# nrf9120_mlm1 register map
Vendor: Nordic Semiconductor; Series: nrf91; File version: 1
CPU: CM4 r0p1, little endian, MPU, FPU, 3 interrupt priority bits
Registers are 32-bit, read-write, reset 0x0 unless marked. A register's access mark holds for its fields unless they carry their own. Offsets are from the block's base; [hi:lo] are bit positions; lines under a group give offsets from that group; {n}, {i} and the like mark numbered series; 'fields as' and 'values as' point back to an identical list.

## USBD — Universal Serial Bus device
Base 0x4001F000
0x00 TASKS_USBDREINIT wo — Resets the whole USBD peripheral. This includes disabling the pull-up on D+.
  [0] TASKS_USBDREINIT
    1=Trigger task
{0x4+4i} TASKS_STARTEPIN[{i}] (i=0..7) wo — Description collection: Captures the EPIN[n].PTR, EPIN[n].MAXCNT and EPIN[n].CONFIG registers values, and enables endpoint IN n to respond to traffic from host
  [0] TASKS_STARTEPIN — Captures the EPIN[n].PTR, EPIN[n].MAXCNT and EPIN[n].CONFIG registers values, and enables endpoint IN n to respond to traffic from host
    1=Trigger task
{0x24+4i} TASKS_STARTISOIN[{i}] (i=0..0) wo — Description collection: Captures the ISOIN[n].PTR, ISOIN[n].MAXCNT and ISOIN[n].CONFIG registers values, and enables sending data on iso endpoint
  [0] TASKS_STARTISOIN — Captures the ISOIN[n].PTR, ISOIN[n].MAXCNT and ISOIN[n].CONFIG registers values, and enables sending data on iso endpoint
    1=Trigger task
{0x28+4i} TASKS_STARTEPOUT[{i}] (i=0..7) wo — Description collection: Captures the EPOUT[n].PTR, EPOUT[n].MAXCNT and EPOUT[n].CONFIG registers values, and enables endpoint n to respond to traffic from host
  [0] TASKS_STARTEPOUT — Captures the EPOUT[n].PTR, EPOUT[n].MAXCNT and EPOUT[n].CONFIG registers values, and enables endpoint n to respond to traffic from host
    1=Trigger task
{0x48+4i} TASKS_STARTISOOUT[{i}] (i=0..0) wo — Description collection: Captures the ISOOUT[n].PTR, ISOOUT[n].MAXCNT and ISOOUT[n].CONFIG registers values, and enables receiving of data on iso endpoint
  [0] TASKS_STARTISOOUT — Captures the ISOOUT[n].PTR, ISOOUT[n].MAXCNT and ISOOUT[n].CONFIG registers values, and enables receiving of data on iso endpoint
    1=Trigger task
0x4C TASKS_EP0RCVOUT wo — Allows OUT data stage on control endpoint 0
  [0] TASKS_EP0RCVOUT
    1=Trigger task
0x50 TASKS_EP0STATUS wo — Allows status stage on control endpoint 0
  [0] TASKS_EP0STATUS
    1=Trigger task
0x54 TASKS_EP0STALL wo — STALLs data and status stage on control endpoint 0
  [0] TASKS_EP0STALL
    1=Trigger task
0x58 TASKS_DPDMDRIVE wo — Forces D+ and D-lines to the state defined in the DPDMVALUE register
  [0] TASKS_DPDMDRIVE
    1=Trigger task
0x5C TASKS_DPDMNODRIVE wo — Stops forcing D+ and D- lines to any state (USB engine takes control)
  [0] TASKS_DPDMNODRIVE
    1=Trigger task
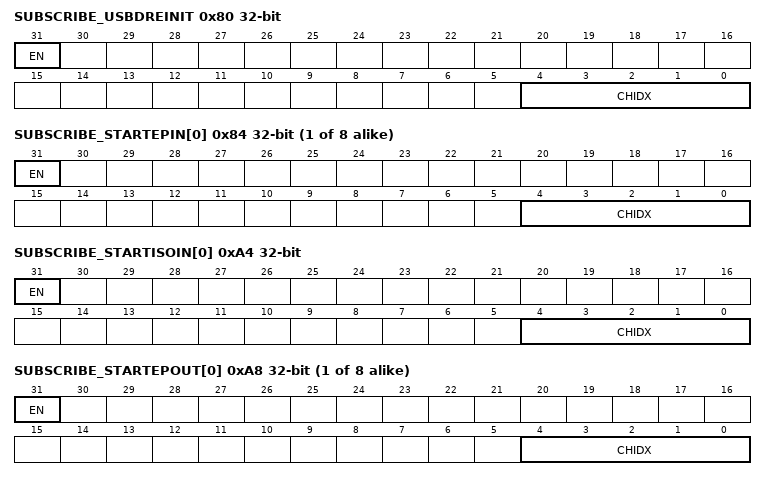
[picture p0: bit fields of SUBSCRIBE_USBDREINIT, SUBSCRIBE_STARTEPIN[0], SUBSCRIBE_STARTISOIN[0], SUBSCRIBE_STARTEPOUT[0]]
0x80 SUBSCRIBE_USBDREINIT — Subscribe configuration for task USBDREINIT
  [31] EN
    0=Disabled (Disable subscription); 1=Enabled (Enable subscription)
  [4:0] CHIDX — Channel that task USBDREINIT will subscribe to
{0x84+4i} SUBSCRIBE_STARTEPIN[{i}] (i=0..7) — Description collection: Subscribe configuration for task STARTEPIN[n]
  [31] EN
    values as SUBSCRIBE_USBDREINIT.EN
  [4:0] CHIDX — Channel that task STARTEPIN[n] will subscribe to
{0xA4+4i} SUBSCRIBE_STARTISOIN[{i}] (i=0..0) — Description collection: Subscribe configuration for task STARTISOIN[n]
  [31] EN
    values as SUBSCRIBE_USBDREINIT.EN
  [4:0] CHIDX — Channel that task STARTISOIN[n] will subscribe to
{0xA8+4i} SUBSCRIBE_STARTEPOUT[{i}] (i=0..7) — Description collection: Subscribe configuration for task STARTEPOUT[n]
  [31] EN
    values as SUBSCRIBE_USBDREINIT.EN
  [4:0] CHIDX — Channel that task STARTEPOUT[n] will subscribe to
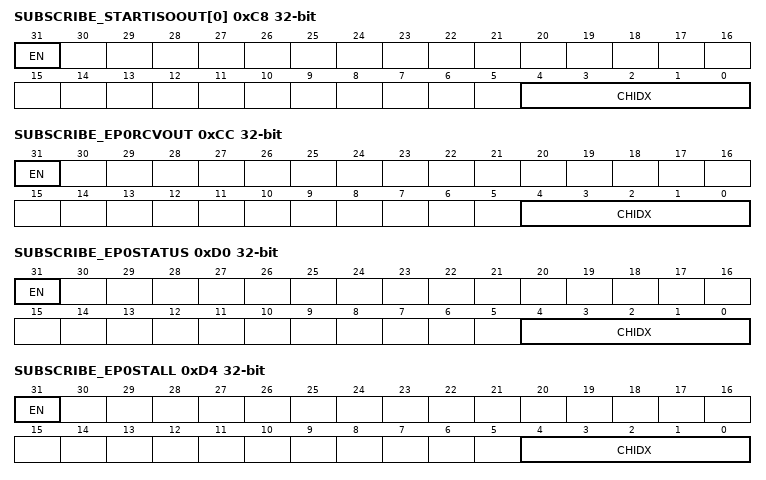
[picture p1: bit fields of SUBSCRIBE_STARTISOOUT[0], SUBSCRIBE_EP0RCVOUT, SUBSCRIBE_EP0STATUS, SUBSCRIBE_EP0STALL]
{0xC8+4i} SUBSCRIBE_STARTISOOUT[{i}] (i=0..0) — Description collection: Subscribe configuration for task STARTISOOUT[n]
  [31] EN
    values as SUBSCRIBE_USBDREINIT.EN
  [4:0] CHIDX — Channel that task STARTISOOUT[n] will subscribe to
0xCC SUBSCRIBE_EP0RCVOUT — Subscribe configuration for task EP0RCVOUT
  [31] EN
    values as SUBSCRIBE_USBDREINIT.EN
  [4:0] CHIDX — Channel that task EP0RCVOUT will subscribe to
0xD0 SUBSCRIBE_EP0STATUS — Subscribe configuration for task EP0STATUS
  [31] EN
    values as SUBSCRIBE_USBDREINIT.EN
  [4:0] CHIDX — Channel that task EP0STATUS will subscribe to
0xD4 SUBSCRIBE_EP0STALL — Subscribe configuration for task EP0STALL
  [31] EN
    values as SUBSCRIBE_USBDREINIT.EN
  [4:0] CHIDX — Channel that task EP0STALL will subscribe to
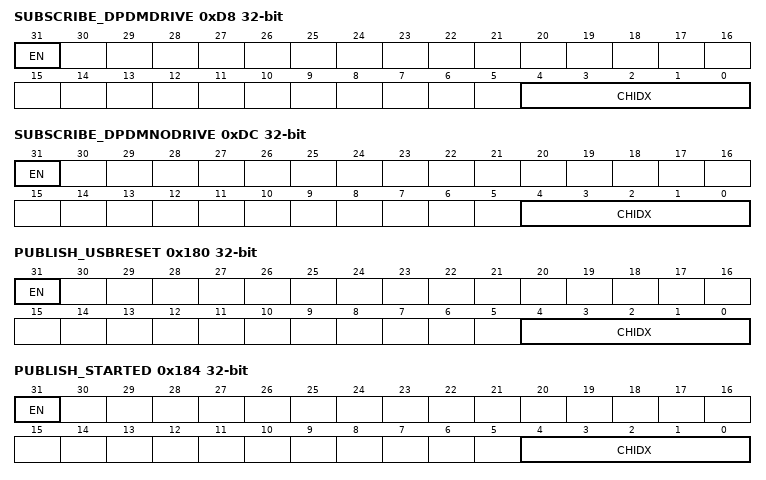
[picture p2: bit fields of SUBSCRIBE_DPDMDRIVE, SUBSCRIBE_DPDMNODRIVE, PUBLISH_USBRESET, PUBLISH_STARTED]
0xD8 SUBSCRIBE_DPDMDRIVE — Subscribe configuration for task DPDMDRIVE
  [31] EN
    values as SUBSCRIBE_USBDREINIT.EN
  [4:0] CHIDX — Channel that task DPDMDRIVE will subscribe to
0xDC SUBSCRIBE_DPDMNODRIVE — Subscribe configuration for task DPDMNODRIVE
  [31] EN
    values as SUBSCRIBE_USBDREINIT.EN
  [4:0] CHIDX — Channel that task DPDMNODRIVE will subscribe to
0x100 EVENTS_USBRESET — Signals that a USB reset condition has been detected on the USB lines
  [0] EVENTS_USBRESET
    0=NotGenerated (Event not generated); 1=Generated (Event generated)
0x104 EVENTS_STARTED — Confirms that the EPIN[n].PTR, EPIN[n].MAXCNT, EPIN[n].CONFIG, or EPOUT[n].PTR, EPOUT[n].MAXCNT and EPOUT[n].CONFIG registers have been captured on all endpoints reported in the EPSTATUS register
  [0] EVENTS_STARTED
    values as EVENTS_USBRESET.EVENTS_USBRESET
{0x108+4i} EVENTS_ENDEPIN[{i}] (i=0..7) — Description collection: The whole EPIN[n] buffer has been consumed. The RAM buffer can be accessed safely by software.
  [0] EVENTS_ENDEPIN — The whole EPIN[n] buffer has been consumed. The RAM buffer can be accessed safely by software.
    values as EVENTS_USBRESET.EVENTS_USBRESET
0x128 EVENTS_EP0DATADONE — An acknowledged data transfer has taken place on the control endpoint
  [0] EVENTS_EP0DATADONE
    values as EVENTS_USBRESET.EVENTS_USBRESET
{0x12C+4i} EVENTS_ENDISOIN[{i}] (i=0..0) — Description collection: The whole ISOIN[n] buffer has been consumed. The RAM buffer can be accessed safely by software.
  [0] EVENTS_ENDISOIN — The whole ISOIN[n] buffer has been consumed. The RAM buffer can be accessed safely by software.
    values as EVENTS_USBRESET.EVENTS_USBRESET
{0x130+4i} EVENTS_ENDEPOUT[{i}] (i=0..7) — Description collection: The whole EPOUT[n] buffer has been consumed. The RAM buffer can be accessed safely by software.
  [0] EVENTS_ENDEPOUT — The whole EPOUT[n] buffer has been consumed. The RAM buffer can be accessed safely by software.
    values as EVENTS_USBRESET.EVENTS_USBRESET
{0x150+4i} EVENTS_ENDISOOUT[{i}] (i=0..0) — Description collection: The whole ISOOUT[n] buffer has been consumed. The RAM buffer can be accessed safely by software.
  [0] EVENTS_ENDISOOUT — The whole ISOOUT[n] buffer has been consumed. The RAM buffer can be accessed safely by software.
    values as EVENTS_USBRESET.EVENTS_USBRESET
0x154 EVENTS_SOF — Signals that a SOF (start of frame) condition has been detected on the USB lines
  [0] EVENTS_SOF
    values as EVENTS_USBRESET.EVENTS_USBRESET
0x158 EVENTS_USBEVENT — An event or an error not covered by specific events has occurred, check EVENTCAUSE register to find the cause
  [0] EVENTS_USBEVENT
    values as EVENTS_USBRESET.EVENTS_USBRESET
0x15C EVENTS_EP0SETUP — A valid SETUP token has been received (and acknowledged) on the control endpoint
  [0] EVENTS_EP0SETUP
    values as EVENTS_USBRESET.EVENTS_USBRESET
0x160 EVENTS_EPDATA — A data transfer has occurred on a data endpoint, indicated by the EPDATASTATUS register
  [0] EVENTS_EPDATA
    values as EVENTS_USBRESET.EVENTS_USBRESET
0x164 EVENTS_ACCESSFAULT — Access to an unavailable USB register has been attempted (software or EasyDMA). This event can get fired even when USBD is not ENABLEd.
  [0] EVENTS_ACCESSFAULT
    values as EVENTS_USBRESET.EVENTS_USBRESET
0x180 PUBLISH_USBRESET — Publish configuration for event USBRESET
  [31] EN
    0=Disabled (Disable publishing); 1=Enabled (Enable publishing)
  [4:0] CHIDX — Channel that event USBRESET will publish to.
0x184 PUBLISH_STARTED — Publish configuration for event STARTED
  [31] EN
    values as PUBLISH_USBRESET.EN
  [4:0] CHIDX — Channel that event STARTED will publish to.
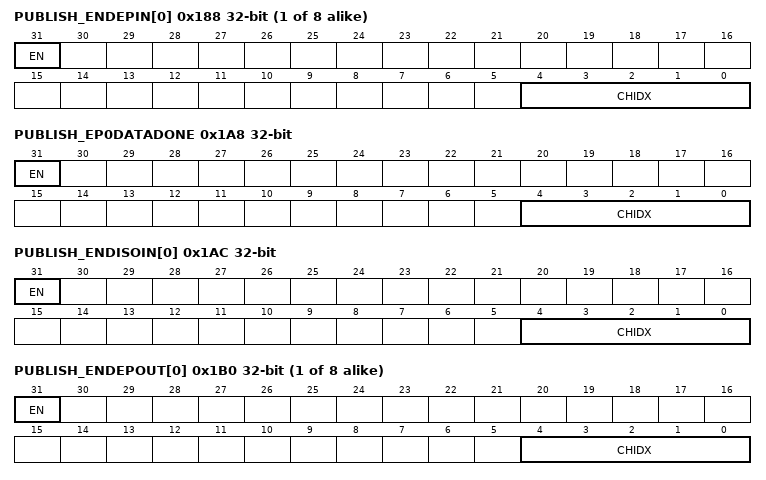
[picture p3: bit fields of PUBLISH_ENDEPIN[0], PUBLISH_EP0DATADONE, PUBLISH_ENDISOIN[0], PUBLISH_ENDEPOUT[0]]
{0x188+4i} PUBLISH_ENDEPIN[{i}] (i=0..7) — Description collection: Publish configuration for event ENDEPIN[n]
  [31] EN
    values as PUBLISH_USBRESET.EN
  [4:0] CHIDX — Channel that event ENDEPIN[n] will publish to.
0x1A8 PUBLISH_EP0DATADONE — Publish configuration for event EP0DATADONE
  [31] EN
    values as PUBLISH_USBRESET.EN
  [4:0] CHIDX — Channel that event EP0DATADONE will publish to.
{0x1AC+4i} PUBLISH_ENDISOIN[{i}] (i=0..0) — Description collection: Publish configuration for event ENDISOIN[n]
  [31] EN
    values as PUBLISH_USBRESET.EN
  [4:0] CHIDX — Channel that event ENDISOIN[n] will publish to.
{0x1B0+4i} PUBLISH_ENDEPOUT[{i}] (i=0..7) — Description collection: Publish configuration for event ENDEPOUT[n]
  [31] EN
    values as PUBLISH_USBRESET.EN
  [4:0] CHIDX — Channel that event ENDEPOUT[n] will publish to.
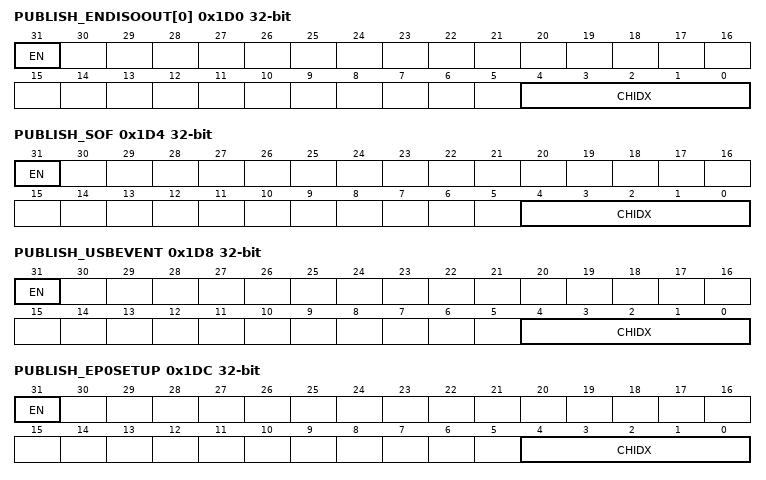
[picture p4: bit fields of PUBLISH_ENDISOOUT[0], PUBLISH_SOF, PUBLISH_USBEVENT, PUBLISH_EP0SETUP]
{0x1D0+4i} PUBLISH_ENDISOOUT[{i}] (i=0..0) — Description collection: Publish configuration for event ENDISOOUT[n]
  [31] EN
    values as PUBLISH_USBRESET.EN
  [4:0] CHIDX — Channel that event ENDISOOUT[n] will publish to.
0x1D4 PUBLISH_SOF — Publish configuration for event SOF
  [31] EN
    values as PUBLISH_USBRESET.EN
  [4:0] CHIDX — Channel that event SOF will publish to.
0x1D8 PUBLISH_USBEVENT — Publish configuration for event USBEVENT
  [31] EN
    values as PUBLISH_USBRESET.EN
  [4:0] CHIDX — Channel that event USBEVENT will publish to.
0x1DC PUBLISH_EP0SETUP — Publish configuration for event EP0SETUP
  [31] EN
    values as PUBLISH_USBRESET.EN
  [4:0] CHIDX — Channel that event EP0SETUP will publish to.
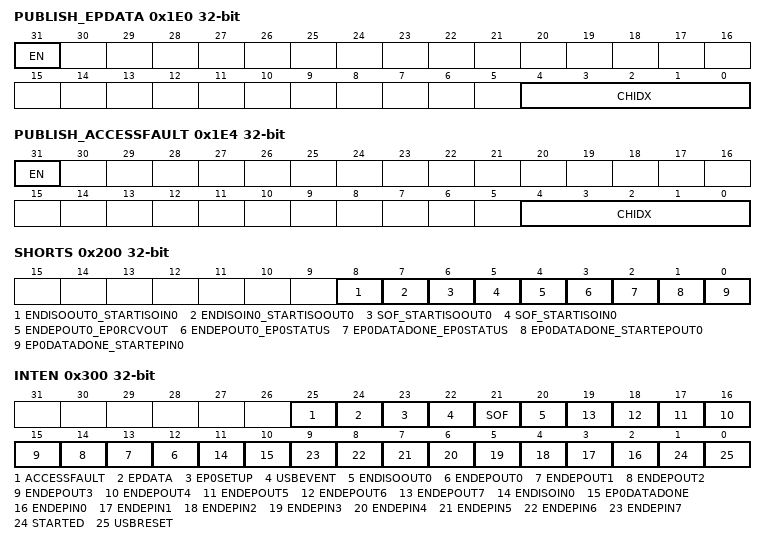
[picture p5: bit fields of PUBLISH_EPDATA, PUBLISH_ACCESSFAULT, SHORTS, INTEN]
0x1E0 PUBLISH_EPDATA — Publish configuration for event EPDATA
  [31] EN
    values as PUBLISH_USBRESET.EN
  [4:0] CHIDX — Channel that event EPDATA will publish to.
0x1E4 PUBLISH_ACCESSFAULT — Publish configuration for event ACCESSFAULT
  [31] EN
    values as PUBLISH_USBRESET.EN
  [4:0] CHIDX — Channel that event ACCESSFAULT will publish to.
0x200 SHORTS — Shortcuts between local events and tasks
  [all] fields
    0=Disabled (Disable shortcut); 1=Enabled (Enable shortcut)
  [8] ENDISOOUT0_STARTISOIN0 — Shortcut between event ENDISOOUT[0] and task STARTISOIN[0]
  [7] ENDISOIN0_STARTISOOUT0 — Shortcut between event ENDISOIN[0] and task STARTISOOUT[0]
  [6] SOF_STARTISOOUT0 — Shortcut between event SOF and task STARTISOOUT[0]
  [5] SOF_STARTISOIN0 — Shortcut between event SOF and task STARTISOIN[0]
  [4] ENDEPOUT0_EP0RCVOUT — Shortcut between event ENDEPOUT[0] and task EP0RCVOUT
  [3] ENDEPOUT0_EP0STATUS — Shortcut between event ENDEPOUT[0] and task EP0STATUS
  [2] EP0DATADONE_EP0STATUS — Shortcut between event EP0DATADONE and task EP0STATUS
  [1] EP0DATADONE_STARTEPOUT0 — Shortcut between event EP0DATADONE and task STARTEPOUT[0]
  [0] EP0DATADONE_STARTEPIN0 — Shortcut between event EP0DATADONE and task STARTEPIN[0]
0x300 INTEN — Enable or disable interrupt
  [all] fields
    0=Disabled; 1=Enabled
  [25] ACCESSFAULT — Enable or disable interrupt for event ACCESSFAULT
  [24] EPDATA — Enable or disable interrupt for event EPDATA
  [23] EP0SETUP — Enable or disable interrupt for event EP0SETUP
  [22] USBEVENT — Enable or disable interrupt for event USBEVENT
  [21] SOF — Enable or disable interrupt for event SOF
  [20] ENDISOOUT0 — Enable or disable interrupt for event ENDISOOUT[0]
  [n+12] ENDEPOUT{n} (n=0..7) — Enable or disable interrupt for event ENDEPOUT[{n}]
  [11] ENDISOIN0 — Enable or disable interrupt for event ENDISOIN[0]
  [10] EP0DATADONE — Enable or disable interrupt for event EP0DATADONE
  [n+2] ENDEPIN{n} (n=0..7) — Enable or disable interrupt for event ENDEPIN[{n}]
  [1] STARTED — Enable or disable interrupt for event STARTED
  [0] USBRESET — Enable or disable interrupt for event USBRESET
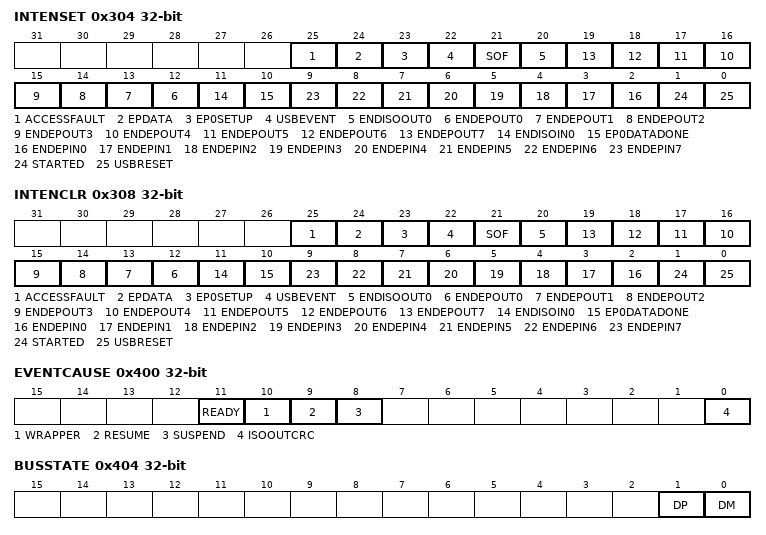
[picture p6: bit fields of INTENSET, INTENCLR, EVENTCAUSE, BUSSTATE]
0x304 INTENSET — Enable interrupt
  [all] fields
    on read: 0=Disabled (Read: Disabled); 1=Enabled (Read: Enabled) | on write: 1=Set (Enable)
  [25] ACCESSFAULT — Write '1' to enable interrupt for event ACCESSFAULT
  [24] EPDATA — Write '1' to enable interrupt for event EPDATA
  [23] EP0SETUP — Write '1' to enable interrupt for event EP0SETUP
  [22] USBEVENT — Write '1' to enable interrupt for event USBEVENT
  [21] SOF — Write '1' to enable interrupt for event SOF
  [20] ENDISOOUT0 — Write '1' to enable interrupt for event ENDISOOUT[0]
  [n+12] ENDEPOUT{n} (n=0..7) — Write '1' to enable interrupt for event ENDEPOUT[{n}]
  [11] ENDISOIN0 — Write '1' to enable interrupt for event ENDISOIN[0]
  [10] EP0DATADONE — Write '1' to enable interrupt for event EP0DATADONE
  [n+2] ENDEPIN{n} (n=0..7) — Write '1' to enable interrupt for event ENDEPIN[{n}]
  [1] STARTED — Write '1' to enable interrupt for event STARTED
  [0] USBRESET — Write '1' to enable interrupt for event USBRESET
0x308 INTENCLR — Disable interrupt
  [all] fields
    on read: 0=Disabled (Read: Disabled); 1=Enabled (Read: Enabled) | on write: 1=Clear (Disable)
  [25] ACCESSFAULT — Write '1' to disable interrupt for event ACCESSFAULT
  [24] EPDATA — Write '1' to disable interrupt for event EPDATA
  [23] EP0SETUP — Write '1' to disable interrupt for event EP0SETUP
  [22] USBEVENT — Write '1' to disable interrupt for event USBEVENT
  [21] SOF — Write '1' to disable interrupt for event SOF
  [20] ENDISOOUT0 — Write '1' to disable interrupt for event ENDISOOUT[0]
  [n+12] ENDEPOUT{n} (n=0..7) — Write '1' to disable interrupt for event ENDEPOUT[{n}]
  [11] ENDISOIN0 — Write '1' to disable interrupt for event ENDISOIN[0]
  [10] EP0DATADONE — Write '1' to disable interrupt for event EP0DATADONE
  [n+2] ENDEPIN{n} (n=0..7) — Write '1' to disable interrupt for event ENDEPIN[{n}]
  [1] STARTED — Write '1' to disable interrupt for event STARTED
  [0] USBRESET — Write '1' to disable interrupt for event USBRESET
0x400 EVENTCAUSE write-1-clears — Details on event that caused the USBEVENT event
  [11] READY — Wrapper has re-initialized SFRs to the proper values. MAC is ready for normal operation. Write '1' to clear.
    0=NotDetected (USBEVENT was not issued due to USBD peripheral ready); 1=Ready (USBD peripheral is ready)
  [10] WRAPPER — USB MAC has been woken up by the wrapper. Reflects the wakesrc bit in usbcs SFR. Write '1' to clear.
    0=NotDetected (Condition not detected); 1=Detected (Condition detected)
  [9] RESUME — Signals that a RESUME condition (K state or activity restart) has been detected on the USB lines. Write '1' to clear.
    0=NotDetected (Resume not detected); 1=Detected (Resume detected)
  [8] SUSPEND — Signals that the USB lines have been seen idle long enough for the device to enter suspend. Write '1' to clear.
    0=NotDetected (Suspend not detected); 1=Detected (Suspend detected)
  [0] ISOOUTCRC — CRC error was detected on isochronous OUT endpoint 8. Write '1' to clear.
    0=NotDetected (No error detected); 1=Detected (Error detected)
0x404 BUSSTATE ro — Provides the logic state of the D+ and D- lines
  [1] DP — State of the D+ line
    0=Low; 1=High
  [0] DM — State of the D- line
    0=Low; 1=High
0x420 HALTED group — Unspecified
  {0x0+4j} EPIN[{j}] (j=0..7) ro — Description collection: IN endpoint halted status. Can be used as is as response to a GetStatus() request to endpoint.
    [15:0] GETSTATUS — IN endpoint halted status. Can be used as is as response to a GetStatus() request to endpoint.
      0=NotHalted (Endpoint is not halted); 1=Halted (Endpoint is halted)
  {0x24+4j} EPOUT[{j}] (j=0..7) ro — Description collection: OUT endpoint halted status. Can be used as is as response to a GetStatus() request to endpoint.
    [15:0] GETSTATUS — OUT endpoint halted status. Can be used as is as response to a GetStatus() request to endpoint.
      values as HALTED.EPIN[0].GETSTATUS
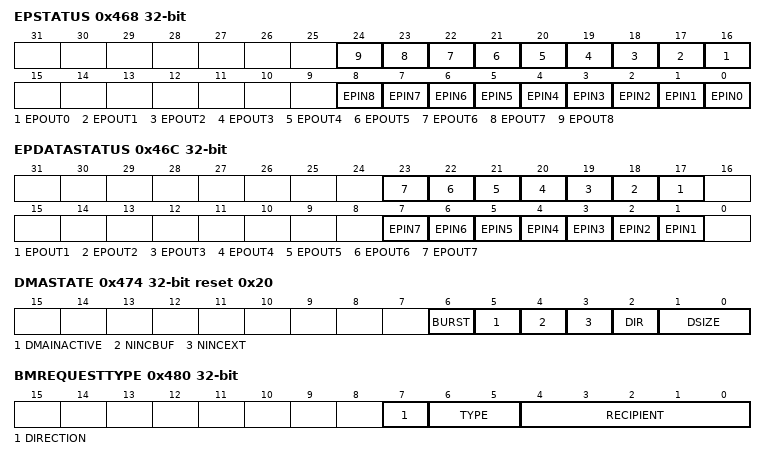
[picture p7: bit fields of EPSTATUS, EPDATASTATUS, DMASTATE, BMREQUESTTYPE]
0x468 EPSTATUS write-1-clears — Provides information on which endpoint's EasyDMA registers have been captured
  [all] fields
    0=NoData (EasyDMA registers have not been captured for this endpoint); 1=DataDone (EasyDMA registers have been captured for this endpoint)
  [n+16] EPOUT{n} (n=0..8) — Endpoint's EasyDMA registers captured state. Write '1' to clear.
  [n] EPIN{n} (n=0..8) — Endpoint's EasyDMA registers captured state. Write '1' to clear.
0x46C EPDATASTATUS write-1-clears — Provides information on which endpoint(s) an acknowledged data transfer has occurred (EPDATA event)
  [n+16] EPOUT{n} (n=1..7) — Acknowledged data transfer on this OUT endpoint. Write '1' to clear.
    0=NotStarted (No acknowledged data transfer on this endpoint); 1=Started (Acknowledged data transfer on this endpoint has occurred)
  [n] EPIN{n} (n=1..7) — Acknowledged data transfer on this IN endpoint. Write '1' to clear.
    0=NotDone (No acknowledged data transfer on this endpoint); 1=DataDone (Acknowledged data transfer on this endpoint has occurred)
0x470 USBADDR ro — Device USB address
  [6:0] ADDR
0x474 DMASTATE ro reset 0x20 — Indicates activity state of the DMA
  [6] BURST — DMA burst
    0=Single transfer; 1=Burst transfer
  [5] DMAINACTIVE — DMA active or not
    0=Active (DMA transfer on-going); 1=Inactive (No DMA transfer on-going)
  [4] NINCBUF — DMA no increment buffer address
    0=NoIncrement (Buffer address is not incremented after every access); 1=Increment (Buffer address is incremented after every access)
  [3] NINCEXT — DMA no increment external memory address
    0=NoIncrement (Data RAM address is not incremented after every access); 1=Increment (Data RAM address is incremented after every access)
  [2] DIR — DMA no increment external memory address
    0=ToRAM (DMA transfers from USB buffer to Data RAM); 1=ToUSB (DMA transfers from Data RAM to USB buffer)
  [1:0] DSIZE — DMA transfer size
    0=8 Bit transfers; 1=16 Bit transfers; 2=32 Bit transfers
0x480 BMREQUESTTYPE ro — SETUP data, byte 0, bmRequestType
  [7] DIRECTION — Data transfer direction
    0=HostToDevice; 1=DeviceToHost
  [6:5] TYPE — Data transfer type
    0=Standard; 1=Class; 2=Vendor
  [4:0] RECIPIENT — Data transfer type
    0=Device; 1=Interface; 2=Endpoint; 3=Other
0x484 BREQUEST ro — SETUP data, byte 1, bRequest
  [7:0] BREQUEST — SETUP data, byte 1, bRequest. Values provides for standard requests only, user must implement Class and Vendor values.
    0=STD_GET_STATUS (Standard request GET_STATUS); 1=STD_CLEAR_FEATURE (Standard request CLEAR_FEATURE); 3=STD_SET_FEATURE (Standard request SET_FEATURE); 5=STD_SET_ADDRESS (Standard request SET_ADDRESS); 6=STD_GET_DESCRIPTOR (Standard request GET_DESCRIPTOR); 7=STD_SET_DESCRIPTOR (Standard request SET_DESCRIPTOR); 8=STD_GET_CONFIGURATION (Standard request GET_CONFIGURATION); 9=STD_SET_CONFIGURATION (Standard request SET_CONFIGURATION); 10=STD_GET_INTERFACE (Standard request GET_INTERFACE); 11=STD_SET_INTERFACE (Standard request SET_INTERFACE); 12=STD_SYNCH_FRAME (Standard request SYNCH_FRAME)
0x488 WVALUEL ro — SETUP data, byte 2, LSB of wValue
  [7:0] WVALUEL
0x48C WVALUEH ro — SETUP data, byte 3, MSB of wValue
  [7:0] WVALUEH
0x490 WINDEXL ro — SETUP data, byte 4, LSB of wIndex
  [7:0] WINDEXL
0x494 WINDEXH ro — SETUP data, byte 5, MSB of wIndex
  [7:0] WINDEXH
0x498 WLENGTHL ro — SETUP data, byte 6, LSB of wLength
  [7:0] WLENGTHL
0x49C WLENGTHH ro — SETUP data, byte 7, MSB of wLength
  [7:0] WLENGTHH
0x4A0 SIZE group — Unspecified
  {0x0+4j} EPOUT[{j}] (j=0..7) — Description collection: Amount of bytes received last in the data stage of this OUT endpoint
    [6:0] SIZE — Amount of bytes received last in the data stage of this OUT endpoint
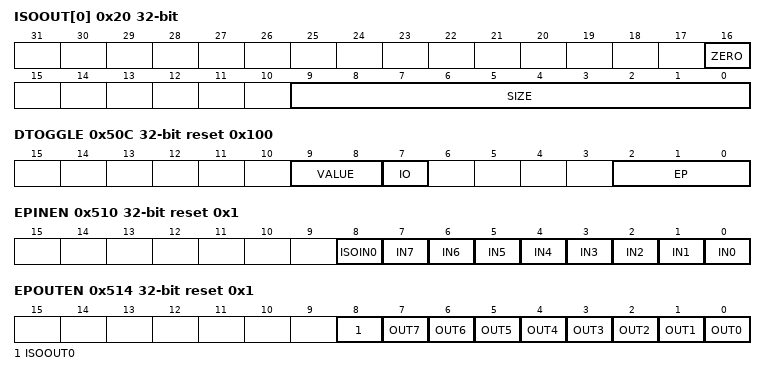
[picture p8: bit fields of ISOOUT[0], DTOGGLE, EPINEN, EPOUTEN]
  {0x20+4j} ISOOUT[{j}] (j=0..0) — Description collection: Amount of bytes received last on this iso OUT data endpoint
    [16] ZERO — Zero-length data packet received
      0=Normal (No zero-length data received, use value in SIZE); 1=ZeroData (Zero-length data received, ignore value in SIZE)
    [9:0] SIZE — Amount of bytes received last on this iso OUT data endpoint
0x500 ENABLE — Enable USB
  [1:0] ENABLE
    0=Disabled (USB peripheral is disabled); 1=Enabled (USB peripheral is enabled)
0x504 USBPULLUP — Control of the USB pull-up
  [0] CONNECT — Control of the USB pull-up on the D+ line
    0=Disabled (Pull-up is disconnected); 1=Enabled (Pull-up is connected to D+)
0x508 DPDMVALUE — State at which the DPDMDRIVE task will force D+ and D-. The DPDMNODRIVE task reverts the control of the lines to MAC IP (no forcing).
  [4:0] STATE — State at which the DPDMDRIVE task will force D+ and D-
    1=Resume (D+ forced low, D- forced high (K state) for a timing pre-set in hardware (50 us or 5 ms, depending on bus state)); 2=J (D+ forced high, D- forced low (J state)); 4=K (D+ forced low, D- forced high (K state)); 8=SE0 (D+ and D- forced low (single-ended 0) (not in first silicon - decide if to be present in final silicon at all)); 16=SE1 (D+ and D- forced high (single-ended 1) (not in first silicon - decide if to be present in final silicon at all))
0x50C DTOGGLE reset 0x100 — Data toggle control and status.
  [9:8] VALUE — Data toggle value
    0=Nop (No action on data toggle when writing the register with this value); 1=Data0 (Data toggle is DATA0 on endpoint set by EP and IO); 2=Data1 (Data toggle is DATA1 on endpoint set by EP and IO)
  [7] IO — Selects IN or OUT endpoint
    0=Out (Selects OUT endpoint); 1=In (Selects IN endpoint)
  [2:0] EP — Select bulk endpoint number
0x510 EPINEN reset 0x1 — Endpoint IN enable
  [8] ISOIN0 — Enable iso IN endpoint
    0=Disable iso IN endpoint 8; 1=Enable iso IN endpoint 8
  [n] IN{n} (n=0..7) — Enable IN endpoint {n}
    0=Disable endpoint IN {n} (no response to IN tokens); 1=Enable endpoint IN {n} (response to IN tokens)
0x514 EPOUTEN reset 0x1 — Endpoint OUT enable
  [8] ISOOUT0 — Enable iso OUT endpoint 8
    0=Disable iso OUT endpoint 8; 1=Enable iso OUT endpoint 8
  [n] OUT{n} (n=0..7) — Enable OUT endpoint {n}
    0=Disable endpoint OUT {n} (no response to OUT tokens); 1=Enable endpoint OUT {n} (response to OUT tokens)
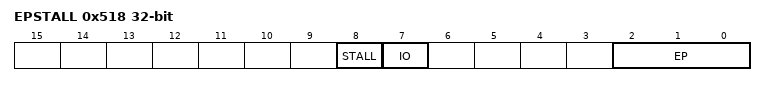
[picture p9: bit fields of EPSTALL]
0x518 EPSTALL wo — STALL endpoints
  [8] STALL — Stall selected endpoint
    0=UnStall (Don't stall selected endpoint); 1=Stall selected endpoint
  [7] IO — Selects IN or OUT endpoint
    0=Out (Selects OUT endpoint); 1=In (Selects IN endpoint)
  [2:0] EP — Select endpoint number
0x51C ISOSPLIT — Controls the split of ISO buffers
  [15:0] SPLIT
    0=OneDir (Full buffer dedicated to either iso IN or OUT); 128=HalfIN (Lower half for IN, upper half for OUT); 0x8000=HalfOUT (Lower half for OUT, upper half for IN); 64=QuartIN (Lower 25 percent for IN, upper 75 percent for OUT); 0x4000=QuartOUT (Lower 25 percent for OUT, upper 75 percent for IN)
0x520 FRAMECNTR ro — Returns the current value of the start of frame counter
  [10:0] FRAMECNTR
0x524 TESTUSBPULLUP — Control of the USB pull-up value, for test purposes
  [1:0] VALUE — Control of the value of USB pull-up on the D+ line (for test mode)
    0=Auto (MAC controls the value of the pull-up (no override)); 2=BusActive (Pull-up value is 1425 to 3090 Ohm); 3=BusIdle (Pull-up is Resume in 900 to 1575 Ohm)
0x528 TSEL reset 0x1 — Trim value for ramTSEL[1:0] on the RamBist interface
  [1:0] RAMTSEL — Trim value for ramTSEL[1:0] on the RamBist interface (tSelInUsb lines)
0x52C LOWPOWER — First silicon only: Controls USBD peripheral low-power mode during USB suspend
  [0] LOWPOWER — Controls USBD peripheral low-power mode during USB suspend
    0=ForceNormal (Software must write this value to exit low power mode and before performing a remote wake-up); 1=LowPower (Software must write this value to enter low power mode after DMA and software have finished interacting with the USB peripheral)
0x530 ISOINCONFIG — Controls the response of the ISO IN endpoint to an IN token when no data is ready to be sent
  [0] RESPONSE
    0=NoResp (Endpoint does not respond in that case); 1=ZeroData (Endpoint responds with a zero-length data packet in that case)
{0x600+0x14*i} EPIN[{i}] (i=0..7) group — Unspecified
  0x00 PTR — Description cluster: Data pointer
    [31:0] PTR — Data pointer. Accepts any address in Data RAM.
  0x04 MAXCNT — Description cluster: Maximum number of bytes to transfer
    [15:0] MAXCNT — Maximum number of bytes to transfer
  0x08 AMOUNT ro — Description cluster: Number of bytes transferred in the last transaction
    [15:0] AMOUNT — Number of bytes transferred in the last transaction
  0x0C CONFIG — Description cluster: Endpoint EasyDMA configuration
    [1:0] DMASIZE — DMA transfer size
      0=Byte (DMA transfer size is 8 bit); 1=Short (DMA transfer size is 16 bit (buffer in Data RAM must be aligned accordingly)); 2=Long (DMA transfer size is 32 bit (buffer in Data RAM must be aligned accordingly))
  0x10 LIST — Description cluster: EasyDMA list type
    [2:0] LIST — List type
      0=Disabled (Normal EasyDMA operation); 1=ArrayList (Use array list (auto-increment of .PTR))
{0x6A0+0x10*i} ISOIN[{i}] (i=0..0) group — Unspecified
  0x00 PTR — Description cluster: Data pointer
    [31:0] PTR — Data pointer. Accepts any address in Data RAM.
  0x04 MAXCNT — Description cluster: Maximum number of bytes to transfer
    [15:0] MAXCNT — Maximum number of bytes to transfer
  0x08 AMOUNT ro — Description cluster: Number of bytes transferred in the last transaction
    [15:0] AMOUNT — Number of bytes transferred in the last transaction
  0x0C CONFIG — Description cluster: Isochronous endpoint EasyDMA configuration
    fields as EPIN[0].CONFIG
{0x700+0x14*i} EPOUT[{i}] (i=0..7) group — Unspecified
  0x00 PTR — Description cluster: Data pointer
    [31:0] PTR — Data pointer. Accepts any address in Data RAM.
  0x04 MAXCNT — Description cluster: Maximum number of bytes to transfer
    [15:0] MAXCNT — Maximum number of bytes to transfer
  0x08 AMOUNT ro — Description cluster: Number of bytes transferred in the last transaction
    [15:0] AMOUNT — Number of bytes transferred in the last transaction
  0x0C CONFIG — Description cluster: Endpoint EasyDMA configuration
    fields as EPIN[0].CONFIG
  0x10 LIST — Description cluster: EasyDMA list type
    fields as EPIN[0].LIST
{0x7A0+0x10*i} ISOOUT[{i}] (i=0..0) group — Unspecified
  0x00 PTR — Description cluster: Data pointer
    [31:0] PTR — Data pointer. Accepts any address in Data RAM.
  0x04 MAXCNT — Description cluster: Maximum number of bytes to transfer
    [15:0] MAXCNT — Maximum number of bytes to transfer
  0x08 AMOUNT ro — Description cluster: Number of bytes transferred in the last transaction
    [15:0] AMOUNT — Number of bytes transferred in the last transaction
  0x0C CONFIG — Description cluster: Isochronous endpoint EasyDMA configuration
    fields as EPIN[0].CONFIG
0x800 RAWADDR — Address to be used for accessing the MAC IP4000
  [10:0] ADDR — IP4000 address space
0x804 RAWDATA — Actual read or write access to the raw IP, using RAWADDR address
  [7:0] DATA
0xFF8 REGRESET reset 0x1 — Registers reset. Writing any value to this register will reset all registers in this peripheral to their reset values. Read access to this register has no consequence. Not implemented in first silicon.
  [0] REGRESET — Writing any value to this register will reset all registers in this peripheral to their reset values. Read access to this register has no consequence.
0xFFC POWER reset 0x1 — Peripheral power control
  [0] POWER — Peripheral power control. The peripheral and its registers will be reset to its initial state by switching the peripheral off and then back on again.
    0=Disabled (Peripheral is powered off); 1=Enabled (Peripheral is powered on)
